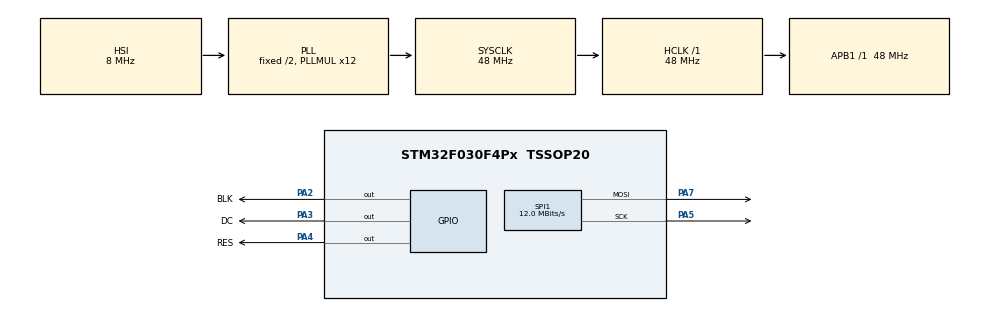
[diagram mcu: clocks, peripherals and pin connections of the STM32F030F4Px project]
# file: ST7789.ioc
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Mcu.Family=STM32F0
Mcu.Name=STM32F030F4Px
Mcu.Package=TSSOP20
PA13.Mode=Serial_Wire
PA13.Signal=SYS_SWDIO
PA14.Mode=Serial_Wire
PA14.Signal=SYS_SWCLK
PA2.GPIO_Label=BLK
PA2.Signal=GPIO_Output
PA3.GPIO_Label=DC
PA3.Signal=GPIO_Output
PA4.GPIO_Label=RES
PA4.Signal=GPIO_Output
PA5.Mode=TX_Only_Simplex_Unidirect_Master
PA5.Signal=SPI1_SCK
PA7.Mode=TX_Only_Simplex_Unidirect_Master
PA7.Signal=SPI1_MOSI
ProjectManager.HeapSize=0x200
ProjectManager.StackSize=0x400
ProjectManager.TargetToolchain=MDK-ARM V5
RCC.AHBFreq_Value=48000000
RCC.APB1Freq_Value=48000000
RCC.APB1TimFreq_Value=48000000
RCC.HCLKFreq_Value=48000000
RCC.PLLMUL=RCC_PLL_MUL12
RCC.SYSCLKFreq_VALUE=48000000
RCC.SYSCLKSource=RCC_SYSCLKSOURCE_PLLCLK
SPI1.BaudRatePrescaler=SPI_BAUDRATEPRESCALER_4
SPI1.CalculateBaudRate=12.0 MBits/s
SPI1.Direction=SPI_DIRECTION_2LINES
SPI1.Mode=SPI_MODE_MASTER
SPI1.VirtualType=VM_MASTER
board=custom

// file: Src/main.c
/* USER CODE BEGIN Header */
/**
  ******************************************************************************
  * @file           : main.c
  * @brief          : Main program body
  ******************************************************************************
  * @attention
  *
  * <h2><center>&copy; Copyright (c) 2020 STMicroelectronics.
  * All rights reserved.</center></h2>
  *
  * This software component is licensed by ST under BSD 3-Clause license,
  * the "License"; You may not use this file except in compliance with the
  * License. You may obtain a copy of the License at:
  *                        opensource.org/licenses/BSD-3-Clause
  *
  ******************************************************************************
  */
/* USER CODE END Header */

#include "main.h"
#include "spi.h"
#include "gpio.h"

/* USER CODE BEGIN Includes */
#include "st7789.h"
/* USER CODE END Includes */

void SystemClock_Config(void);

int main(void)
{

  /* MCU Configuration--------------------------------------------------------*/

  /* Reset of all peripherals, Initializes the Flash interface and the Systick. */
  HAL_Init();

  /* Configure the system clock */
  SystemClock_Config();

  /* Initialize all configured peripherals */
  MX_GPIO_Init();
  MX_SPI1_Init();
  /* USER CODE BEGIN 2 */
  HAL_GPIO_WritePin(BLK_GPIO_Port, BLK_Pin, GPIO_PIN_SET);
  /* USER CODE END 2 */

  /* Infinite loop */
  while (1)
  {
    ST7789_Init(240, 240);
	  // Инициализация входа для кнопки
    // Тест вывода основных цветов
    ST7789_FillScreen(BLACK);
    ST7789_SetBL(100);

//    uint16_t color = RGB565(255, 0, 0);
//    ST7789_FillScreen(color);
//    HAL_Delay(500);
//
//    color = RGB565(0, 255, 0);
//    ST7789_FillScreen(color);
//    HAL_Delay(500);

//    color = RGB565(50, 55, 50);
//    ST7789_FillScreen(color);
//    HAL_Delay(500);

//    color = RGB565(0, 0, 255);
//    ST7789_FillScreen(color);
//    HAL_Delay(500);

//    color = RGB565(255, 255, 0);
//    ST7789_FillScreen(color);
//    HAL_Delay(500);

//    color = RGB565(255, 0, 255);
//    ST7789_FillScreen(color);
//    HAL_Delay(500);

//    color = RGB565(0, 255, 255);
//    ST7789_FillScreen(color);
//    HAL_Delay(500);

//    color = RGB565(255, 255, 255);
//    ST7789_FillScreen(color);
//    HAL_Delay(500);
//
//    ST7789_FillScreen(BLACK);
//    ST7789_SetBL(100);

    ST7789_FillScreen(BLACK);
    ST7789_SetBL(100);
		ST7789_DrawChar_5x8(100, 100, RGB565(0, 255, 255), RGB565(0, 0, 0), 0, 'A');
		ST7789_DrawChar_7x11(60, 60, RGB565(0, 255, 255), RGB565(0, 0, 0), 0, 0xBB);

    ST7789_print_5x8(10, 30, RGB565(0, 255, 255), RGB565(0, 0, 0), 0, "Привет");
    ST7789_print_7x11(40, 40, RGB565(0, 255, 255), RGB565(0, 0, 0), 0, "Welcome");

    HAL_Delay(10000);

//		for (uint8_t y = 0; y<240 ; y++) {
//			ST7789_DrawLine(120, 120, 239, y, RGB565(y+10, 0, 0));
//		}
//
//		for (uint8_t x = 0; x<240 ; x++) {
//			ST7789_DrawLine(120, 120, x, 239, RGB565(0, x+10, 0));
//		}
//
//		for (uint8_t y = 0; y<240 ; y++) {
//			ST7789_DrawLine(120, 120, 0, y, RGB565(0, 0, y+10));
//		}
//
//		for (uint8_t x = 0; x<240 ; x++) {
//			ST7789_DrawLine(120, 120, x, 0, RGB565(x+10, x+10, x+10));
//		}
//    HAL_Delay(1000);

//    ST7789_FillScreen(BLACK);
//    ST7789_SetBL(100);

//    for (uint8_t x = 0; x < 240 ; x = x + 20) {
//			for (uint8_t y = 0; y < 240; y = y + 20) {
//				ST7789_DrawRectangleFilled(x + 3, y + 3, x + 17, y + 17, RGB565(x, y, 0));
//				ST7789_DrawRectangle(x + 2, y + 2, x + 19, y + 19, RGB565(250, 250, 250));
//			}
//		}
//    HAL_Delay(1000);

//    ST7789_FillScreen(BLACK);
//    ST7789_SetBL(100);

//    for (uint8_t x = 0; x < 240 ; x = x + 20) {
//			for (uint8_t y = 0; y < 240; y = y + 20) {
//        ST7789_DrawCircleFilled(x + 10, y + 10, 8, RGB565(x, y, 0));
//        ST7789_DrawCircle(x + 10, y + 10, 9, RGB565(0, y, x));
//			}
//		}
//    HAL_Delay(1000);

//    ST7789_FillScreen(BLACK);
 //   ST7789_SetBL(100);

  }
}

void SystemClock_Config(void)
{
  RCC_OscInitTypeDef RCC_OscInitStruct = {0};
  RCC_ClkInitTypeDef RCC_ClkInitStruct = {0};

  /** Initializes the CPU, AHB and APB busses clocks
  */
  RCC_OscInitStruct.OscillatorType = RCC_OSCILLATORTYPE_HSI;
  RCC_OscInitStruct.HSIState = RCC_HSI_ON;
  RCC_OscInitStruct.HSICalibrationValue = RCC_HSICALIBRATION_DEFAULT;
  RCC_OscInitStruct.PLL.PLLState = RCC_PLL_ON;
  RCC_OscInitStruct.PLL.PLLSource = RCC_PLLSOURCE_HSI;
  RCC_OscInitStruct.PLL.PLLMUL = RCC_PLL_MUL12;
  RCC_OscInitStruct.PLL.PREDIV = RCC_PREDIV_DIV1;
  if (HAL_RCC_OscConfig(&RCC_OscInitStruct) != HAL_OK)
  {
    Error_Handler();
  }
  /** Initializes the CPU, AHB and APB busses clocks
  */
  RCC_ClkInitStruct.ClockType = RCC_CLOCKTYPE_HCLK|RCC_CLOCKTYPE_SYSCLK
                              |RCC_CLOCKTYPE_PCLK1;
  RCC_ClkInitStruct.SYSCLKSource = RCC_SYSCLKSOURCE_PLLCLK;
  RCC_ClkInitStruct.AHBCLKDivider = RCC_SYSCLK_DIV1;
  RCC_ClkInitStruct.APB1CLKDivider = RCC_HCLK_DIV1;

  if (HAL_RCC_ClockConfig(&RCC_ClkInitStruct, FLASH_LATENCY_1) != HAL_OK)
  {
    Error_Handler();
  }
}

void Error_Handler(void)
{
}

/************************ (C) COPYRIGHT STMicroelectronics *****END OF FILE****/
